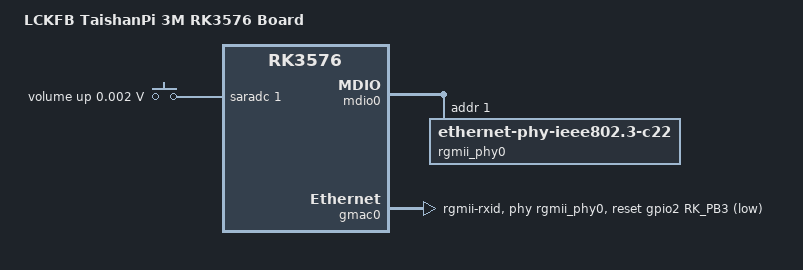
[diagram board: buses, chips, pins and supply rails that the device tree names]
// SPDX-License-Identifier: (GPL-2.0+ OR MIT)
/*
 * Copyright (c) 2023 Rockchip Electronics Co., Ltd.
 * Copyright (c) 2026 LCKFB <lckfb@sz-jlc.com>
 *
 * TaishanPi-3M RK3576 Board U-Boot device tree
 */

/dts-v1/;
#include "rk3576.dtsi"
#include "rk3576-u-boot.dtsi"
#include <dt-bindings/input/input.h>

/ {
	model = "LCKFB TaishanPi 3M RK3576 Board";
	compatible = "lckfb,tspi-3m-rk3576", "rockchip,rk3576";

	adc-keys {
		compatible = "adc-keys";
		io-channels = <&saradc 1>;
		io-channel-names = "buttons";
		keyup-threshold-microvolt = <1800000>;
		u-boot,dm-pre-reloc;
		status = "okay";

		volumeup-key {
			u-boot,dm-pre-reloc;
			linux,code = <KEY_VOLUMEUP>;
			label = "volume up";
			press-threshold-microvolt = <1750>;
		};
	};
};

/*-----------------------------------------------------------
 * MDIO0 Bus: RGMII PHY Node
 *----------------------------------------------------------*/
&mdio0 {
	rgmii_phy0: phy@1 {
		compatible = "ethernet-phy-ieee802.3-c22";
		reg = <0x1>;
		clocks = <&cru REFCLKO25M_GMAC0_OUT>;
	};
};

/*-----------------------------------------------------------
 * GMAC0 Main Controller Node
 *----------------------------------------------------------*/
&gmac0 {
	phy-mode = "rgmii-rxid";
	clock_in_out = "output";

	snps,reset-gpio = <&gpio2 RK_PB3 GPIO_ACTIVE_LOW>;
	snps,reset-active-low;
	snps,reset-delays-us = <0 20000 100000>;

	pinctrl-names = "default";
	pinctrl-0 = <&eth0m0_miim
			&eth0m0_tx_bus2
			&eth0m0_rx_bus2
			&eth0m0_rgmii_clk
			&eth0m0_rgmii_bus
			&eth0m0_mclk>;

	tx_delay = <0x24>;

	phy-handle = <&rgmii_phy0>;
	status = "okay";
};

&gmac1 {
	status = "disabled";
};
